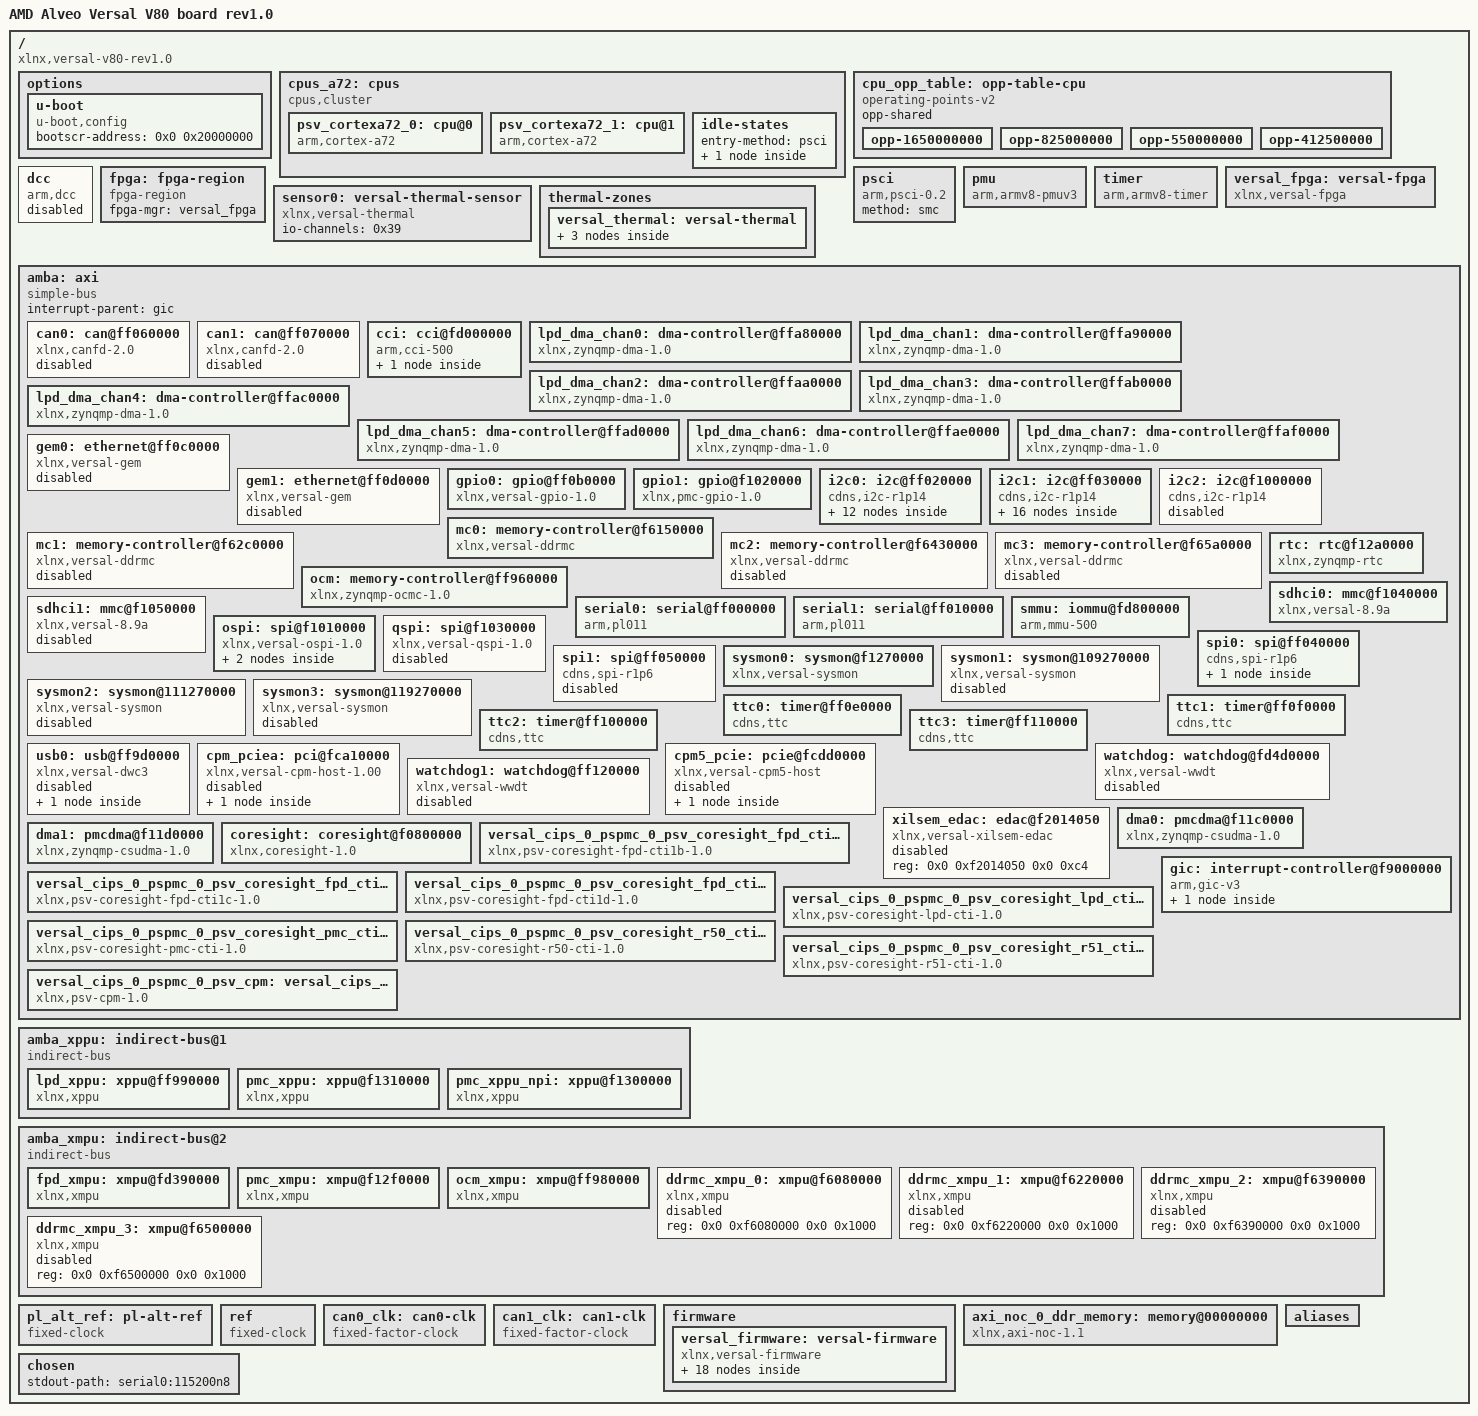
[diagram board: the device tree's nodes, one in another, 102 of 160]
/dts-v1/;
/ {
        compatible = "xlnx,versal-v80-rev1.0", "xlnx,versal";
        #address-cells = <0x2>;
        #size-cells = <0x2>;
        model = "AMD Alveo Versal V80 board rev1.0";
        board = "v80";
        device_id = "xcv80";
        slrcount = <0x3>;
        family = "Versal";
        speed_grade = "2MHP";

        options {

                u-boot {
                        compatible = "u-boot,config";
                        bootscr-address = <0x0 0x20000000>;
                };
        };

        cpus_a72: cpus {
                #address-cells = <0x1>;
                #size-cells = <0x0>;
                compatible = "cpus,cluster";
                #ranges-address-cells = <0x2>;
                #ranges-size-cells = <0x2>;
                phandle = <0x9e>;

                psv_cortexa72_0: cpu@0 {
                        compatible = "arm,cortex-a72", "arm,armv8";
                        device_type = "cpu";
                        enable-method = "psci";
                        operating-points-v2 = <&cpu_opp_table>;
                        reg = <0x0>;
                        cpu-idle-states = <&CPU_SLEEP_0>;
                        power-domains = <&versal_firmware 0x18110003>;
                        clocks = <&versal_clk 0x4d>;
                        xlnx,timestamp-clk-freq = <0x5f5e0a4>;
                        xlnx,pss-ref-clk-freq = <0x1fca034>;
                        stamp-frequency = <0x5f5e0a4>;
                        xlnx,ip-name = "psv_cortexa72";
                        xlnx,cpu-clk-freq-hz = <0x6258fa4d>;
                        cpu-frequency = <0x6258fa4d>;
                        bus-handle = <0x1>;
                        phandle = <0x9f>;
                };

                psv_cortexa72_1: cpu@1 {
                        compatible = "arm,cortex-a72", "arm,armv8";
                        device_type = "cpu";
                        enable-method = "psci";
                        operating-points-v2 = <&cpu_opp_table>;
                        reg = <0x1>;
                        cpu-idle-states = <&CPU_SLEEP_0>;
                        power-domains = <&versal_firmware 0x18110004>;
                        xlnx,timestamp-clk-freq = <0x5f5e0a4>;
                        xlnx,pss-ref-clk-freq = <0x1fca034>;
                        stamp-frequency = <0x5f5e0a4>;
                        xlnx,ip-name = "psv_cortexa72";
                        xlnx,cpu-clk-freq-hz = <0x6258fa4d>;
                        cpu-frequency = <0x6258fa4d>;
                        bus-handle = <0x1>;
                        phandle = <0xa0>;
                };

                idle-states {
                        entry-method = "psci";

                        CPU_SLEEP_0: cpu-sleep-0 {
                                compatible = "arm,idle-state";
                                arm,psci-suspend-param = <0x40000000>;
                                local-timer-stop;
                                entry-latency-us = <0x12c>;
                                exit-latency-us = <0x258>;
                                min-residency-us = <0x2710>;
                                phandle = <0x73>;
                        };
                };
        };

        cpu_opp_table: opp-table-cpu {
                compatible = "operating-points-v2";
                opp-shared;
                phandle = <0x72>;

                opp-1650000000 {
                        opp-hz = <0x0 0x62590080>;
                        clock-latency-ns = <0x7a120>;
                        opp-microvolt = <0xf4240>;
                };

                opp-825000000 {
                        opp-hz = <0x0 0x312c8040>;
                        clock-latency-ns = <0x7a120>;
                        opp-microvolt = <0xf4240>;
                };

                opp-550000000 {
                        opp-hz = <0x0 0x20c85580>;
                        clock-latency-ns = <0x7a120>;
                        opp-microvolt = <0xf4240>;
                };

                opp-412500000 {
                        opp-hz = <0x0 0x18964020>;
                        clock-latency-ns = <0x7a120>;
                        opp-microvolt = <0xf4240>;
                };
        };

        dcc: dcc {
                compatible = "arm,dcc";
                status = "disabled";
                bootph-all;
                phandle = <0xa9>;
        };

        fpga: fpga-region {
                compatible = "fpga-region";
                fpga-mgr = <&versal_fpga>;
                #address-cells = <0x2>;
                #size-cells = <0x2>;
                phandle = <0xaa>;
        };

        psci: psci {
                compatible = "arm,psci-0.2";
                method = "smc";
                phandle = <0xab>;
        };

        pmu {
                compatible = "arm,armv8-pmuv3";
                interrupt-parent = <&gic>;
                interrupts = <0x1 0x7 0x304>;
        };

        timer: timer {
                compatible = "arm,armv8-timer";
                interrupt-parent = <&gic>;
                interrupts = <0x1 0xd 0x4 0x1 0xe 0x4 0x1 0xb 0x4 0x1 0xa 0x4>;
                phandle = <0xac>;
        };

        versal_fpga: versal-fpga {
                compatible = "xlnx,versal-fpga";
                phandle = <0x92>;
        };

        sensor0: versal-thermal-sensor {
                compatible = "xlnx,versal-thermal";
                #thermal-sensor-cells = <0x0>;
                io-channels = <0x39>;
                io-channel-names = "sysmon-temp-channel";
                phandle = <0x94>;
        };

        thermal-zones {

                versal_thermal: versal-thermal {
                        polling-delay-passive = <0xfa>;
                        polling-delay = <0x3e8>;
                        thermal-sensors = <0x94>;
                        phandle = <0xad>;

                        trips {

                                temp_alert: temp-alert {
                                        temperature = <0x11170>;
                                        hysteresis = <0x0>;
                                        type = "passive";
                                        phandle = <0xae>;
                                };

                                ot_crit: ot-crit {
                                        temperature = <0x1e848>;
                                        hysteresis = <0x0>;
                                        type = "critical";
                                        phandle = <0xaf>;
                                };
                        };
                };
        };

        amba: axi {
                compatible = "simple-bus";
                #address-cells = <0x2>;
                #size-cells = <0x2>;
                ranges;
                interrupt-parent = <&gic>;
                bootph-all;
                phandle = <0x1>;

                can0: can@ff060000 {
                        compatible = "xlnx,canfd-2.0";
                        status = "disabled";
                        reg = <0x0 0xff060000 0x0 0x6000>;
                        interrupts = <0x0 0x14 0x4>;
                        interrupt-parent = <&gic>;
                        clock-names = "can_clk", "s_axi_aclk";
                        rx-fifo-depth = <0x40>;
                        tx-mailbox-count = <0x20>;
                        clocks = <&can0_clk>,
                         <&versal_clk 0x52>;
                        power-domains = <&versal_firmware 0x1822401f>;
                        phandle = <0xb0>;
                };

                can1: can@ff070000 {
                        compatible = "xlnx,canfd-2.0";
                        status = "disabled";
                        reg = <0x0 0xff070000 0x0 0x6000>;
                        interrupts = <0x0 0x15 0x4>;
                        interrupt-parent = <&gic>;
                        clock-names = "can_clk", "s_axi_aclk";
                        rx-fifo-depth = <0x40>;
                        tx-mailbox-count = <0x20>;
                        clocks = <&can1_clk>,
                         <&versal_clk 0x52>;
                        power-domains = <&versal_firmware 0x18224020>;
                        phandle = <0xb1>;
                };

                cci: cci@fd000000 {
                        compatible = "arm,cci-500";
                        status = "okay";
                        reg = <0x0 0xfd000000 0x0 0x10000>;
                        ranges = <0x0 0x0 0xfd000000 0xa0000>;
                        #address-cells = <0x1>;
                        #size-cells = <0x1>;
                        xlnx,ip-name = "psv_fpd_maincci";
                        phandle = <0x44>;

                        cci_pmu: pmu@10000 {
                                compatible = "arm,cci-500-pmu,r0";
                                reg = <0x10000 0x90000>;
                                interrupt-parent = <&gic>;
                                interrupts = <0x0 0x6a 0x4 0x0 0x6a 0x4 0x0 0x6a 0x4 0x0 0x6a 0x4 0x0 0x6a 0x4 0x0 0x6a 0x4 0x0 0x6a 0x4 0x0 0x6a 0x4>;
                                phandle = <0xb2>;
                        };
                };

                lpd_dma_chan0: dma-controller@ffa80000 {
                        compatible = "xlnx,zynqmp-dma-1.0";
                        status = "okay";
                        reg = <0x0 0xffa80000 0x0 0x1000>;
                        interrupts = <0x0 0x3c 0x4>;
                        interrupt-parent = <&gic>;
                        clock-names = "clk_main", "clk_apb";
                        xlnx,dma-type = <0x1>;
                        #dma-cells = <0x1>;
                        xlnx,bus-width = <0x40>;
                        clocks = <&versal_clk 0x51>,
                         <&versal_clk 0x52>;
                        power-domains = <&versal_firmware 0x18224035>;
                        xlnx,is-cache-coherent = <0x0>;
                        xlnx,ip-name = "psv_adma";
                        xlnx,dma-mode = <0x1>;
                        phandle = <0x66>;
                };

                lpd_dma_chan1: dma-controller@ffa90000 {
                        compatible = "xlnx,zynqmp-dma-1.0";
                        status = "okay";
                        reg = <0x0 0xffa90000 0x0 0x1000>;
                        interrupts = <0x0 0x3d 0x4>;
                        interrupt-parent = <&gic>;
                        clock-names = "clk_main", "clk_apb";
                        xlnx,dma-type = <0x1>;
                        #dma-cells = <0x1>;
                        xlnx,bus-width = <0x40>;
                        clocks = <&versal_clk 0x51>,
                         <&versal_clk 0x52>;
                        power-domains = <&versal_firmware 0x18224036>;
                        xlnx,is-cache-coherent = <0x0>;
                        xlnx,ip-name = "psv_adma";
                        xlnx,dma-mode = <0x1>;
                        phandle = <0x67>;
                };

                lpd_dma_chan2: dma-controller@ffaa0000 {
                        compatible = "xlnx,zynqmp-dma-1.0";
                        status = "okay";
                        reg = <0x0 0xffaa0000 0x0 0x1000>;
                        interrupts = <0x0 0x3e 0x4>;
                        interrupt-parent = <&gic>;
                        clock-names = "clk_main", "clk_apb";
                        xlnx,dma-type = <0x1>;
                        #dma-cells = <0x1>;
                        xlnx,bus-width = <0x40>;
                        clocks = <&versal_clk 0x51>,
                         <&versal_clk 0x52>;
                        power-domains = <&versal_firmware 0x18224037>;
                        xlnx,is-cache-coherent = <0x0>;
                        xlnx,ip-name = "psv_adma";
                        xlnx,dma-mode = <0x1>;
                        phandle = <0x68>;
                };

                lpd_dma_chan3: dma-controller@ffab0000 {
                        compatible = "xlnx,zynqmp-dma-1.0";
                        status = "okay";
                        reg = <0x0 0xffab0000 0x0 0x1000>;
                        interrupts = <0x0 0x3f 0x4>;
                        interrupt-parent = <&gic>;
                        clock-names = "clk_main", "clk_apb";
                        xlnx,dma-type = <0x1>;
                        #dma-cells = <0x1>;
                        xlnx,bus-width = <0x40>;
                        clocks = <&versal_clk 0x51>,
                         <&versal_clk 0x52>;
                        power-domains = <&versal_firmware 0x18224038>;
                        xlnx,is-cache-coherent = <0x0>;
                        xlnx,ip-name = "psv_adma";
                        xlnx,dma-mode = <0x1>;
                        phandle = <0x69>;
                };

                lpd_dma_chan4: dma-controller@ffac0000 {
                        compatible = "xlnx,zynqmp-dma-1.0";
                        status = "okay";
                        reg = <0x0 0xffac0000 0x0 0x1000>;
                        interrupts = <0x0 0x40 0x4>;
                        interrupt-parent = <&gic>;
                        clock-names = "clk_main", "clk_apb";
                        xlnx,dma-type = <0x1>;
                        #dma-cells = <0x1>;
                        xlnx,bus-width = <0x40>;
                        clocks = <&versal_clk 0x51>,
                         <&versal_clk 0x52>;
                        power-domains = <&versal_firmware 0x18224039>;
                        xlnx,is-cache-coherent = <0x0>;
                        xlnx,ip-name = "psv_adma";
                        xlnx,dma-mode = <0x1>;
                        phandle = <0x6a>;
                };

                lpd_dma_chan5: dma-controller@ffad0000 {
                        compatible = "xlnx,zynqmp-dma-1.0";
                        status = "okay";
                        reg = <0x0 0xffad0000 0x0 0x1000>;
                        interrupts = <0x0 0x41 0x4>;
                        interrupt-parent = <&gic>;
                        clock-names = "clk_main", "clk_apb";
                        xlnx,dma-type = <0x1>;
                        #dma-cells = <0x1>;
                        xlnx,bus-width = <0x40>;
                        clocks = <&versal_clk 0x51>,
                         <&versal_clk 0x52>;
                        power-domains = <&versal_firmware 0x1822403a>;
                        xlnx,is-cache-coherent = <0x0>;
                        xlnx,ip-name = "psv_adma";
                        xlnx,dma-mode = <0x1>;
                        phandle = <0x6b>;
                };

                lpd_dma_chan6: dma-controller@ffae0000 {
                        compatible = "xlnx,zynqmp-dma-1.0";
                        status = "okay";
                        reg = <0x0 0xffae0000 0x0 0x1000>;
                        interrupts = <0x0 0x42 0x4>;
                        interrupt-parent = <&gic>;
                        clock-names = "clk_main", "clk_apb";
                        xlnx,dma-type = <0x1>;
                        #dma-cells = <0x1>;
                        xlnx,bus-width = <0x40>;
                        clocks = <&versal_clk 0x51>,
                         <&versal_clk 0x52>;
                        power-domains = <&versal_firmware 0x1822403b>;
                        xlnx,is-cache-coherent = <0x0>;
                        xlnx,ip-name = "psv_adma";
                        xlnx,dma-mode = <0x1>;
                        phandle = <0x6c>;
                };

                lpd_dma_chan7: dma-controller@ffaf0000 {
                        compatible = "xlnx,zynqmp-dma-1.0";
                        status = "okay";
                        reg = <0x0 0xffaf0000 0x0 0x1000>;
                        interrupts = <0x0 0x43 0x4>;
                        interrupt-parent = <&gic>;
                        clock-names = "clk_main", "clk_apb";
                        xlnx,dma-type = <0x1>;
                        #dma-cells = <0x1>;
                        xlnx,bus-width = <0x40>;
                        clocks = <&versal_clk 0x51>,
                         <&versal_clk 0x52>;
                        power-domains = <&versal_firmware 0x1822403c>;
                        xlnx,is-cache-coherent = <0x0>;
                        xlnx,ip-name = "psv_adma";
                        xlnx,dma-mode = <0x1>;
                        phandle = <0x6d>;
                };

                gem0: ethernet@ff0c0000 {
                        compatible = "xlnx,versal-gem", "cdns,gem";
                        status = "disabled";
                        reg = <0x0 0xff0c0000 0x0 0x1000>;
                        interrupts = <0x0 0x38 0x4 0x0 0x38 0x4>;
                        interrupt-parent = <&gic>;
                        clock-names = "pclk", "hclk", "tx_clk", "rx_clk", "tsu_clk";
                        #address-cells = <0x1>;
                        #size-cells = <0x0>;
                        clocks = <&versal_clk 0x52>,
                         <&versal_clk 0x58>,
                         <&versal_clk 0x31>,
                         <&versal_clk 0x30>,
                         <&versal_clk 0x2b>;
                        power-domains = <&versal_firmware 0x18224019>;
                        phandle = <0xb3>;
                };

                gem1: ethernet@ff0d0000 {
                        compatible = "xlnx,versal-gem", "cdns,gem";
                        status = "disabled";
                        reg = <0x0 0xff0d0000 0x0 0x1000>;
                        interrupts = <0x0 0x3a 0x4 0x0 0x3a 0x4>;
                        interrupt-parent = <&gic>;
                        clock-names = "pclk", "hclk", "tx_clk", "rx_clk", "tsu_clk";
                        #address-cells = <0x1>;
                        #size-cells = <0x0>;
                        clocks = <&versal_clk 0x52>,
                         <&versal_clk 0x59>,
                         <&versal_clk 0x33>,
                         <&versal_clk 0x32>,
                         <&versal_clk 0x2b>;
                        power-domains = <&versal_firmware 0x1822401a>;
                        phandle = <0xb4>;
                };

                gpio0: gpio@ff0b0000 {
                        compatible = "xlnx,versal-gpio-1.0";
                        status = "okay";
                        reg = <0x0 0xff0b0000 0x0 0x1000>;
                        interrupts = <0x0 0xd 0x4>;
                        interrupt-parent = <&gic>;
                        #gpio-cells = <0x2>;
                        gpio-controller;
                        #interrupt-cells = <0x2>;
                        interrupt-controller;
                        clocks = <&versal_clk 0x52>;
                        power-domains = <&versal_firmware 0x18224023>;
                        xlnx,ip-name = "psv_gpio";
                        emio-gpio-width = "";
                        gpio-line-names = [49 32 43 5F 51 53 46 50 5F 53 43 4C 00 49 32 43 5F 51 53 46 50 5F 53 44 41 00 49 32 43 5F 4D 41 49 4E 5F 53 43 4C 00 49 32 43 5F 4D 41 49 4E 5F 53 44 41 00 49 32 43 5F 4D 41 49 4E 5F 52 53 54 5F 42 00 49 32 43 5F 4D 41 49 4E 5F 49 4E 54 52 5F 42 00 51 53 46 50 34 5F 49 4F 45 58 50 5F 52 53 54 00 51 53 46 50 33 5F 49 4F 45 58 50 5F 52 53 54 00 4C 50 44 5F 55 41 52 54 30 5F 52 58 44 00 4C 50 44 5F 55 41 52 54 30 5F 54 58 44 00 00 00 53 50 49 30 5F 53 43 4C 4B 00 49 32 43 5F 51 53 46 50 5F 52 53 54 5F 42 00 49 32 43 5F 51 53 46 50 5F 49 4E 54 52 5F 42 00 53 50 49 30 5F 43 53 5F 42 00 53 50 49 30 5F 4D 49 53 4F 00 53 50 49 30 5F 4D 4F 53 49 00 51 53 46 50 31 5F 49 4F 45 58 50 5F 52 53 54 00 51 53 46 50 32 5F 49 4F 45 58 50 5F 52 53 54 00 4C 50 44 5F 55 41 52 54 31 5F 54 58 44 00 4C 50 44 5F 55 41 52 54 31 5F 52 58 44 00 42 4F 41 52 44 5F 53 54 41 54 55 53 5F 4C 45 44 5F 52 00 42 4F 41 52 44 5F 53 54 41 54 55 53 5F 4C 45 44 5F 47 00 42 4F 41 52 44 5F 53 54 41 54 55 53 5F 4C 45 44 5F 42 00 00 00 00 00 00 00 00 00 00 00 00 00 00 00 00 00 00 00 00 00 00 00 00 00 00 00 00 00 00 00 00 00 00];
                        phandle = <0x57>;
                };

                gpio1: gpio@f1020000 {
                        compatible = "xlnx,pmc-gpio-1.0";
                        status = "okay";
                        reg = <0x0 0xf1020000 0x0 0x1000>;
                        interrupts = <0x0 0x7a 0x4>;
                        interrupt-parent = <&gic>;
                        #gpio-cells = <0x2>;
                        gpio-controller;
                        #interrupt-cells = <0x2>;
                        interrupt-controller;
                        clocks = <&versal_clk 0x3d>;
                        power-domains = <&versal_firmware 0x1822402c>;
                        xlnx,ip-name = "psv_pmc_gpio";
                        gpio-line-names = [00 00 00 00 00 00 00 00 00 00 00 42 4F 41 52 44 5F 49 44 00 4F 53 50 49 5F 52 45 53 45 54 5F 42 00 00 00 00 00 00 00 00 00 00 00 00 50 43 49 45 5F 52 53 54 31 5F 42 00 50 43 49 45 5F 52 53 54 32 5F 42 00 51 53 46 50 34 5F 41 43 54 5F 4C 45 44 00 51 53 46 50 34 5F 4C 4E 4B 5F 47 52 5F 4C 45 44 00 51 53 46 50 34 5F 4C 4E 4B 5F 59 4C 5F 4C 45 44 00 45 4E 5F 33 56 33 5F 4D 43 49 4F 00 51 53 46 50 33 5F 41 43 54 5F 4C 45 44 00 51 53 46 50 33 5F 4C 4E 4B 5F 47 52 5F 4C 45 44 00 51 53 46 50 33 5F 4C 4E 4B 5F 59 4C 5F 4C 45 44 00 50 47 5F 33 56 33 5F 4D 43 49 4F 00 51 53 46 50 31 5F 41 43 54 5F 4C 45 44 00 51 53 46 50 31 5F 4C 4E 4B 5F 47 52 5F 4C 45 44 00 51 53 46 50 31 5F 4C 4E 4B 5F 59 4C 5F 4C 45 44 00 00 51 53 46 50 32 5F 41 43 54 5F 4C 45 44 00 51 53 46 50 32 5F 4C 4E 4B 5F 47 52 5F 4C 45 44 00 51 53 46 50 32 5F 4C 4E 4B 5F 59 4C 5F 4C 45 44 00 50 47 5F 31 32 56 5F 41 55 58 32 00 50 43 49 45 5F 45 58 50 31 5F 50 45 52 53 54 42 00 50 43 49 45 5F 45 58 50 32 5F 50 45 52 53 54 42 00 50 43 49 45 5F 45 58 50 33 5F 50 45 52 53 54 42 00 4D 43 49 4F 5F 50 32 5F 46 4C 45 58 49 4F 30 5F 42 55 46 00 50 4D 43 5F 55 41 52 54 31 5F 54 58 44 00 50 4D 43 5F 55 41 52 54 31 5F 52 58 44 00 50 43 49 45 5F 45 58 50 31 5F 43 50 52 53 4E 54 42 00 50 43 49 45 5F 45 58 50 32 5F 43 50 52 53 4E 54 42 00 50 43 49 45 5F 45 58 50 33 5F 43 50 52 53 4E 54 42 00 55 53 42 5F 50 52 45 53 00 00 00 00 00 00 00 00 00 00 00 00 00 00 00 00 00 00 00 00 00 00 00 00 00 00 00 00 00 00 00 00 00 00 00 00 00 00 00 00 00 00 00 00 00 00 00 00 00 00 00 00 00 00 00 00 00 00 00 00 00 00 00 00 00];
                        phandle = <0x2b>;
                };

                i2c0: i2c@ff020000 {
                        compatible = "cdns,i2c-r1p14";
                        status = "okay";
                        reg = <0x0 0xff020000 0x0 0x1000>;
                        interrupts = <0x0 0xe 0x4>;
                        interrupt-parent = <&gic>;
                        clock-frequency = <0x186a0>;
                        #address-cells = <0x1>;
                        #size-cells = <0x0>;
                        clocks = <&versal_clk 0x62>;
                        power-domains = <&versal_firmware 0x1822401d>;
                        xlnx,clock-freq = <0x5f5e0a4>;
                        xlnx,i2c-clk-freq-hz = <0x5f5e0a4>;
                        xlnx,ip-name = "psv_i2c";
                        xlnx,iic-board-interface = "custom";
                        phandle = <0x52>;

                        regulator_u50: regulator@60 {
                                compatible = "isil,isl68224";
                                reg = <0x60>;
                                phandle = <0xb5>;
                        };

                        regulator_uXX: regulator@61 {
                                compatible = "isil,isl68224";
                                reg = <0x61>;
                                phandle = <0xb6>;
                        };

                        sensor_u30: temp-sensor@1a {
                                compatible = "onnn,cat34ts02", "jedec,jc-42.4-temp";
                                reg = <0x1a>;
                                phandle = <0xb7>;
                        };

                        gpio_u43: gpio@20 {
                                compatible = "ti,tca6416";
                                reg = <0x20>;
                                gpio-controller;
                                #gpio-cells = <0x2>;
                                interrupt-parent = <&gpio0>;
                                interrupts = <0x5 0x1>;
                                gpio-line-names = "TCRITn", "EN_VCC_FUSE", "FRU_EEPRM_WP", "PCIE_SMB_LT_EN", "IOEXP_POR_B", "CG_CONFI_GPIO0", "EN_DIMM", "DMB_PRSNT_B", "12V_AUX1_SENSE0_N", "12V_AUX1_SENSE1_N", "12V_AUX2_SENSE0_N", "12V_AUX2_SENSE1_N", "PG_3V3_QSFP", "DIMM_PWRGD", "BRD_PWRGD", "HBM_PWRGD";
                                phandle = <0xb8>;
                        };

                        ina_u48: power-sensor@40 {
                                compatible = "ti,ina3221";
                                reg = <0x40>;
                                #address-cells = <0x1>;
                                #size-cells = <0x0>;
                                phandle = <0xb9>;

                                input@0 {
                                        reg = <0x0>;
                                        label = "VR_12V";
                                        shunt-resistor-micro-ohms = <0x7d0>;
                                };

                                input@1 {
                                        reg = <0x1>;
                                        label = "VR_3V3";
                                        shunt-resistor-micro-ohms = <0x7d0>;
                                };

                                input@2 {
                                        reg = <0x2>;
                                        label = "VR_3V3_QSFP";
                                        shunt-resistor-micro-ohms = <0x7d0>;
                                };
                        };

                        ina_u49: power-sensor@41 {
                                compatible = "ti,ina3221";
                                reg = <0x41>;
                                #address-cells = <0x1>;
                                #size-cells = <0x0>;
                                phandle = <0xba>;

                                input@0 {
                                        reg = <0x0>;
                                        label = "VR_1V2_VCCO_DIMM";
                                        shunt-resistor-micro-ohms = <0x7d0>;
                                };

                                input@1 {
                                        reg = <0x1>;
                                        label = "VR_12V_AUX1";
                                        shunt-resistor-micro-ohms = <0x7d0>;
                                };

                                input@2 {
                                        reg = <0x2>;
                                        label = "VR_12V_AUX2";
                                        shunt-resistor-micro-ohms = <0x7d0>;
                                };
                        };
                };

                i2c1: i2c@ff030000 {
                        compatible = "cdns,i2c-r1p14";
                        status = "okay";
                        reg = <0x0 0xff030000 0x0 0x1000>;
                        interrupts = <0x0 0xf 0x4>;
                        interrupt-parent = <&gic>;
                        clock-frequency = <0x186a0>;
                        #address-cells = <0x1>;
                        #size-cells = <0x0>;
                        clocks = <&versal_clk 0x63>;
                        power-domains = <&versal_firmware 0x1822401e>;
                        xlnx,clock-freq = <0x5f5e0a4>;
                        xlnx,i2c-clk-freq-hz = <0x5f5e0a4>;
                        xlnx,ip-name = "psv_i2c";
                        xlnx,iic-board-interface = "custom";
                        phandle = <0x53>;

                        qsfp_power: gpio@21 {
                                compatible = "ti,tca6408";
                                reg = <0x21>;
                                gpio-controller;
                                #gpio-cells = <0x2>;
                                interrupt-parent = <&gpio0>;
                                interrupts = <0xe 0x1>;
                                gpio-line-names = "EN_3V3_QSFP1", "EN_3V3_QSFP2", "EN_3V3_QSFP3", "EN_3V3_QSFP4", "PG_3V3_QSFP1", "PG_3V3_QSFP2", "PG_3V3_QSFP3", "PG_3V3_QSFP4";
                                phandle = <0xbb>;
                        };

                        i2c_qsfp1: i2c-mux@70 {
                                compatible = "nxp,pca9545";
                                #address-cells = <0x1>;
                                #size-cells = <0x0>;
                                #interrupt-cells = <0x2>;
                                reg = <0x70>;
                                interrupt-parent = <&gpio0>;
                                interrupts = <0xe 0x1>;
                                interrupt-controller;
                                phandle = <0x97>;

                                i2c@0 {
                                        #address-cells = <0x1>;
                                        #size-cells = <0x0>;
                                        reg = <0x0>;

                                        qsfp1: gpio@20 {
                                                compatible = "ti,tca6408";
                                                reg = <0x20>;
                                                gpio-controller;
                                                #gpio-cells = <0x2>;
                                                interrupt-parent = <&i2c_qsfp1>;
                                                interrupts = <0x2 0x1>;
                                                gpio-line-names = "QSFP1_MODSELL", "QSFP1_RESETL", "QSFP1_LPMODE", "QSFP1_MODPRSL", "QSFP1_INTR_B", "", "", "";
                                                phandle = <0xbc>;
                                        };
                                };

                                i2c@1 {
                                        #address-cells = <0x1>;
                                        #size-cells = <0x0>;
                                        reg = <0x1>;
                                };

                                i2c@2 {
                                        #address-cells = <0x1>;
                                        #size-cells = <0x0>;
                                        reg = <0x2>;

                                        qsfp2: gpio@20 {
                                                compatible = "ti,tca6408";
                                                reg = <0x20>;
                                                gpio-controller;
                                                #gpio-cells = <0x2>;
                                                interrupt-parent = <&i2c_qsfp1>;
                                                interrupts = <0x2 0x1>;
                                                gpio-line-names = "QSFP2_MODSELL", "QSFP2_RESETL", "QSFP2_LPMODE", "QSFP2_MODPRSL", "QSFP2_INTR_B", "", "", "";
                                                phandle = <0xbd>;
                                        };
                                };

                                i2c@3 {
                                        #address-cells = <0x1>;
                                        #size-cells = <0x0>;
                                        reg = <0x3>;
                                };
                        };

                        i2c_qsfp3: i2c-mux@71 {
                                compatible = "nxp,pca9545";
                                #address-cells = <0x1>;
                                #size-cells = <0x0>;
                                #interrupt-cells = <0x2>;
                                reg = <0x70>;
                                interrupt-parent = <&gpio0>;
                                interrupts = <0xe 0x1>;
                                interrupt-controller;
                                phandle = <0x98>;

                                i2c@0 {
                                        #address-cells = <0x1>;
                                        #size-cells = <0x0>;
                                        reg = <0x0>;

                                        qsfp3: gpio@20 {
                                                compatible = "ti,tca6408";
                                                reg = <0x20>;
                                                gpio-controller;
                                                #gpio-cells = <0x2>;
                                                interrupt-parent = <&i2c_qsfp3>;
                                                interrupts = <0x2 0x1>;
                                                gpio-line-names = "QSFP3_MODSELL", "QSFP3_RESETL", "QSFP3_LPMODE", "QSFP3_MODPRSL", "QSFP3_INTR_B", "", "", "";
                                                phandle = <0xbe>;
                                        };
                                };

                                i2c@1 {
                                        #address-cells = <0x1>;
                                        #size-cells = <0x0>;
                                        reg = <0x1>;
                                };

                                i2c@2 {
                                        #address-cells = <0x1>;
                                        #size-cells = <0x0>;
                                        reg = <0x2>;

                                        qsfp4: gpio@20 {
                                                compatible = "ti,tca6408";
                                                reg = <0x20>;
                                                gpio-controller;
                                                #gpio-cells = <0x2>;
                                                interrupt-parent = <&i2c_qsfp3>;
                                                interrupts = <0x2 0x1>;
                                                gpio-line-names = "QSFP4_MODSELL", "QSFP4_RESETL", "QSFP4_LPMODE", "QSFP4_MODPRSL", "QSFP4_INTR_B", "", "", "";
                                                phandle = <0xbf>;
                                        };
                                };

                                i2c@3 {
                                        #address-cells = <0x1>;
                                        #size-cells = <0x0>;
                                        reg = <0x3>;
                                };
                        };

                        pcie: i2c-mux@72 {
                                compatible = "nxp,pca9545";
                                #address-cells = <0x1>;
                                #size-cells = <0x0>;
                                #interrupt-cells = <0x2>;
                                reg = <0x72>;
                                interrupt-parent = <&gpio0>;
                                interrupts = <0xe 0x1>;
                                interrupt-controller;
                                phandle = <0xc0>;
                        };
                };

                i2c2: i2c@f1000000 {
                        compatible = "cdns,i2c-r1p14";
                        status = "disabled";
                        reg = <0x0 0xf1000000 0x0 0x1000>;
                        interrupts = <0x0 0x7b 0x4>;
                        interrupt-parent = <&gic>;
                        clock-frequency = <0x186a0>;
                        #address-cells = <0x1>;
                        #size-cells = <0x0>;
                        clocks = <&versal_clk 0x3e>;
                        power-domains = <&versal_firmware 0x1822402d>;
                        phandle = <0xc1>;
                };

                mc0: memory-controller@f6150000 {
                        compatible = "xlnx,versal-ddrmc";
                        status = "okay";
                        reg = <0x0 0xf6150000 0x0 0x2000 0x0 0xf6070000 0x0 0x20000>;
                        reg-names = "base", "noc";
                        interrupts = <0x0 0x93 0x4>;
                        interrupt-parent = <&gic>;
                        phandle = <0xc2>;
                };

                mc1: memory-controller@f62c0000 {
                        compatible = "xlnx,versal-ddrmc";
                        status = "disabled";
                        reg = <0x0 0xf62c0000 0x0 0x2000 0x0 0xf6210000 0x0 0x20000>;
                        reg-names = "base", "noc";
                        interrupts = <0x0 0x93 0x4>;
                        interrupt-parent = <&gic>;
                        phandle = <0xc3>;
                };

                mc2: memory-controller@f6430000 {
                        compatible = "xlnx,versal-ddrmc";
                        status = "disabled";
                        reg = <0x0 0xf6430000 0x0 0x2000 0x0 0xf6380000 0x0 0x20000>;
                        reg-names = "base", "noc";
                        interrupts = <0x0 0x93 0x4>;
                        interrupt-parent = <&gic>;
                        phandle = <0xc4>;
                };

                mc3: memory-controller@f65a0000 {
                        compatible = "xlnx,versal-ddrmc";
                        status = "disabled";
                        reg = <0x0 0xf65a0000 0x0 0x2000 0x0 0xf64f0000 0x0 0x20000>;
                        reg-names = "base", "noc";
                        interrupts = <0x0 0x93 0x4>;
                        interrupt-parent = <&gic>;
                        phandle = <0xc5>;
                };

                ocm: memory-controller@ff960000 {
                        compatible = "xlnx,zynqmp-ocmc-1.0";
                        reg = <0x0 0xff960000 0x0 0x1000>;
                        interrupts = <0x0 0xa 0x4>;
                        interrupt-parent = <&gic>;
                        phandle = <0xc6>;
                };

                rtc: rtc@f12a0000 {
                        compatible = "xlnx,zynqmp-rtc";
                        status = "okay";
                        reg = <0x0 0xf12a0000 0x0 0x100>;
                        interrupt-names = "alarm", "sec";
                        interrupts = <0x0 0x8e 0x4 0x0 0x8f 0x4>;
                        interrupt-parent = <&gic>;
                        calibration = <0x7fff>;
                        power-domains = <&versal_firmware 0x18224034>;
                        xlnx,ip-name = "psv_pmc_rtc";
                        phandle = <0x3a>;
                };

                sdhci0: mmc@f1040000 {
                        compatible = "xlnx,versal-8.9a", "arasan,sdhci-8.9a";
                        status = "okay";
                        reg = <0x0 0xf1040000 0x0 0x10000>;
                        interrupts = <0x0 0x7e 0x4>;
                        interrupt-parent = <&gic>;
                        clock-names = "clk_xin", "clk_ahb", "gate";
                        #clock-cells = <0x1>;
                        clock-output-names = "clk_out_sd0", "clk_in_sd0";
                        clocks = <&versal_clk 0x3b>,
                         <&versal_clk 0x52>,
                         <&versal_clk 0x4a>;
                        power-domains = <&versal_firmware 0x1822402e>;
                        xlnx,sd-board-interface = "custom";
                        xlnx,is-cache-coherent = <0x0>;
                        xlnx,clk-50-ddr-otap-dly = <0x5>;
                        xlnx,clk-50-sdr-itap-dly = <0x2c>;
                        xlnx,has-emio = <0x0>;
                        clock-frequency = <0xbebc149>;
                        xlnx,clk-100-sdr-otap-dly = <0x0>;
                        xlnx,mio-bank = <0x0>;
                        xlnx,ip-name = "psv_pmc_sd";
                        xlnx,bus-width = <0x8>;
                        xlnx,card-detect = <0x0>;
                        xlnx,has-wp = <0x0>;
                        xlnx,has-cd = <0x0>;
                        xlnx,slot-type = <0x1>;
                        xlnx,clk-50-sdr-otap-dly = <0x5>;
                        xlnx,clk-50-ddr-itap-dly = <0x1e>;
                        xlnx,has-power = <0x0>;
                        xlnx,clk-200-sdr-otap-dly = <0x2>;
                        xlnx,sdio-clk-freq-hz = <0xbebc149>;
                        xlnx,write-protect = <0x0>;
                        non-removable;
                        disable-wp;
                        no-sd;
                        no-sdio;
                        cap-mmc-hw-reset;
                        bus-width = <0x8>;
                        phandle = <0x2c>;
                };

                sdhci1: mmc@f1050000 {
                        compatible = "xlnx,versal-8.9a", "arasan,sdhci-8.9a";
                        status = "disabled";
                        reg = <0x0 0xf1050000 0x0 0x10000>;
                        interrupts = <0x0 0x80 0x4>;
                        interrupt-parent = <&gic>;
                        clock-names = "clk_xin", "clk_ahb", "gate";
                        #clock-cells = <0x1>;
                        clock-output-names = "clk_out_sd1", "clk_in_sd1";
                        clocks = <&versal_clk 0x3c>,
                         <&versal_clk 0x52>,
                         <&versal_clk 0x4a>;
                        power-domains = <&versal_firmware 0x1822402f>;
                        phandle = <0xc7>;
                };

                serial0: serial@ff000000 {
                        compatible = "arm,pl011", "arm,primecell";
                        status = "okay";
                        reg = <0x0 0xff000000 0x0 0x1000>;
                        interrupts = <0x0 0x12 0x4>;
                        interrupt-parent = <&gic>;
                        reg-io-width = <0x4>;
                        clock-names = "uartclk", "apb_pclk";
                        bootph-all;
                        clocks = <&versal_clk 0x5c>,
                         <&versal_clk 0x52>;
                        power-domains = <&versal_firmware 0x18224021>;
                        xlnx,clock-freq = <0x5f5e0a4>;
                        u-boot,dm-pre-reloc;
                        xlnx,uart-board-interface = "custom";
                        xlnx,has-modem = <0x0>;
                        xlnx,ip-name = "psv_sbsauart";
                        xlnx,baudrate = <0x1c200>;
                        cts-override;
                        port-number = <0x0>;
                        xlnx,uart-clk-freq-hz = <0x5f5e0a4>;
                        phandle = <0x50>;
                };

                serial1: serial@ff010000 {
                        compatible = "arm,pl011", "arm,primecell";
                        status = "okay";
                        reg = <0x0 0xff010000 0x0 0x1000>;
                        interrupts = <0x0 0x13 0x4>;
                        interrupt-parent = <&gic>;
                        reg-io-width = <0x4>;
                        clock-names = "uartclk", "apb_pclk";
                        bootph-all;
                        clocks = <&versal_clk 0x5d>,
                         <&versal_clk 0x52>;
                        power-domains = <&versal_firmware 0x18224022>;
                        xlnx,clock-freq = <0x5f5e0a4>;
                        u-boot,dm-pre-reloc;
                        xlnx,uart-board-interface = "custom";
                        xlnx,has-modem = <0x0>;
                        xlnx,ip-name = "psv_sbsauart";
                        xlnx,baudrate = <0x1c200>;
                        cts-override;
                        port-number = <0x0>;
                        xlnx,uart-clk-freq-hz = <0x5f5e0a4>;
                        phandle = <0x51>;
                };

                smmu: iommu@fd800000 {
                        compatible = "arm,mmu-500";
                        status = "okay";
                        reg = <0x0 0xfd800000 0x0 0x40000>;
                        stream-match-mask = <0x7c00>;
                        #iommu-cells = <0x1>;
                        #global-interrupts = <0x1>;
                        interrupts = <0x0 0x6b 0x4 0x0 0x6b 0x4 0x0 0x6b 0x4 0x0 0x6b 0x4 0x0 0x6b 0x4 0x0 0x6b 0x4 0x0 0x6b 0x4 0x0 0x6b 0x4 0x0 0x6b 0x4 0x0 0x6b 0x4 0x0 0x6b 0x4 0x0 0x6b 0x4 0x0 0x6b 0x4 0x0 0x6b 0x4 0x0 0x6b 0x4 0x0 0x6b 0x4 0x0 0x6b 0x4 0x0 0x6b 0x4 0x0 0x6b 0x4 0x0 0x6b 0x4 0x0 0x6b 0x4 0x0 0x6b 0x4 0x0 0x6b 0x4 0x0 0x6b 0x4 0x0 0x6b 0x4 0x0 0x6b 0x4 0x0 0x6b 0x4 0x0 0x6b 0x4 0x0 0x6b 0x4 0x0 0x6b 0x4 0x0 0x6b 0x4 0x0 0x6b 0x4 0x0 0x6b 0x4>;
                        interrupt-parent = <&gic>;
                        xlnx,ip-name = "psv_fpd_smmutcu";
                        phandle = <0x4f>;
                };

                ospi: spi@f1010000 {
                        compatible = "xlnx,versal-ospi-1.0", "cdns,qspi-nor";
                        status = "okay";
                        reg = <0x0 0xf1010000 0x0 0x10000 0x0 0xc0000000 0x0 0x20000000>;
                        interrupts = <0x0 0x7c 0x4>;
                        interrupt-parent = <&gic>;
                        cdns,fifo-depth = <0x100>;
                        cdns,fifo-width = <0x4>;
                        cdns,is-dma = <0x1>;
                        cdns,trigger-address = <0xc0000000>;
                        #address-cells = <0x1>;
                        #size-cells = <0x0>;
                        clocks = <&versal_clk 0x3a>;
                        power-domains = <&versal_firmware 0x1822402a>;
                        reset-names = "qspi";
                        resets = <&versal_reset 0xc10402e>;
                        is-stacked = <0x0>;
                        xlnx,is-cache-coherent = <0x0>;
                        xlnx,clock-freq = <0xbebc149>;
                        xlnx,ip-name = "psv_pmc_ospi";
                        xlnx,ospi-clk-freq-hz = <0xbebc149>;
                        is-dual = <0x0>;
                        xlnx,ospi-mode = <0x0>;
                        bus-num = <0x2>;
                        num-cs = <0x1>;
                        phandle = <0x2a>;

                        ospi_flash: flash@0 {
                                compatible = "mt35xu02g", "micron,m25p80", "jedec,spi-nor";
                                reg = <0x0>;
                                #address-cells = <0x1>;
                                #size-cells = <0x1>;
                                cdns,read-delay = <0x0>;
                                cdns,tshsl-ns = <0x0>;
                                cdns,tsd2d-ns = <0x0>;
                                cdns,tchsh-ns = <0x1>;
                                cdns,tslch-ns = <0x1>;
                                spi-tx-bus-width = <0x8>;
                                spi-rx-bus-width = <0x8>;
                                spi-max-frequency = <0x1312d00>;
                                no-wp;
                                reset-gpios = <&gpio1 0xc 0x1>;
                                phandle = <0xc8>;

                                partition@0 {
                                        label = "spi0-flash0";
                                        reg = <0x0 0x8000000>;
                                };
                        };
                };

                qspi: spi@f1030000 {
                        compatible = "xlnx,versal-qspi-1.0";
                        status = "disabled";
                        reg = <0x0 0xf1030000 0x0 0x1000>;
                        interrupts = <0x0 0x7d 0x4>;
                        interrupt-parent = <&gic>;
                        clock-names = "ref_clk", "pclk";
                        #address-cells = <0x1>;
                        #size-cells = <0x0>;
                        clocks = <&versal_clk 0x39>,
                         <&versal_clk 0x52>;
                        power-domains = <&versal_firmware 0x1822402b>;
                        phandle = <0xc9>;
                };

                spi0: spi@ff040000 {
                        compatible = "cdns,spi-r1p6";
                        status = "okay";
                        reg = <0x0 0xff040000 0x0 0x1000>;
                        interrupts = <0x0 0x10 0x4>;
                        interrupt-parent = <&gic>;
                        clock-names = "ref_clk", "pclk";
                        #address-cells = <0x1>;
                        #size-cells = <0x0>;
                        clocks = <&versal_clk 0x5e>,
                         <&versal_clk 0x52>;
                        power-domains = <&versal_firmware 0x1822401b>;
                        xlnx,spi-board-interface = "custom";
                        xlnx,has-ss0 = <0x1>;
                        xlnx,ip-name = "psv_spi";
                        xlnx,has-ss1 = <0x0>;
                        num-cs = <0x1>;
                        xlnx,spi-clk-freq-hz = <0xbebc149>;
                        xlnx,has-ss2 = <0x0>;
                        phandle = <0x54>;

                        flash@0 {
                                compatible = "jedec,spi-nor";
                                spi-max-frequency = <0x7ed6b40>;
                                reg = <0x0>;
                        };
                };

                spi1: spi@ff050000 {
                        compatible = "cdns,spi-r1p6";
                        status = "disabled";
                        reg = <0x0 0xff050000 0x0 0x1000>;
                        interrupts = <0x0 0x11 0x4>;
                        interrupt-parent = <&gic>;
                        clock-names = "ref_clk", "pclk";
                        #address-cells = <0x1>;
                        #size-cells = <0x0>;
                        clocks = <&versal_clk 0x5f>,
                         <&versal_clk 0x52>;
                        power-domains = <&versal_firmware 0x1822401c>;
                        phandle = <0xca>;
                };

                sysmon0: sysmon@f1270000 {
                        compatible = "xlnx,versal-sysmon";
                        #io-channel-cells = <0x0>;
                        reg = <0x0 0xf1270000 0x0 0x4000>;
                        interrupts = <0x0 0x90 0x4>;
                        xlnx,numchannels = "";
                        #address-cells = <0x2>;
                        #size-cells = <0x2>;
                        xlnx,nodeid = <0x18224055>;
                        xlnx,sat-63-desc = "PS , FPD , satellite";
                        xlnx,sat-17-x = <0x35e5>;
                        xlnx,sat-1-desc = "PMC , system , ADC";
                        xlnx,sat-9-x = <0x6ed4>;
                        xlnx,sat-17-y = <0x676f>;
                        xlnx,sat-19-desc = "VNOC , satellite";
                        xlnx,sat-20-desc = "HBM , Satellite , (right)";
                        xlnx,sat-9-y = <0x772d>;
                        xlnx,sat-22-x = <0x21a7>;
                        xlnx,ip-name = "psv_pmc_sysmon";
                        xlnx,sat-22-y = <0x7362>;
                        xlnx,sat-16-desc = "HBM , Satellite , (left)";
                        xlnx,sat-9-desc = "Clocking , column , satellite";
                        xlnx,sat-26-x = <0xf56>;
                        xlnx,sat-28-desc = "Clocking , column , satellite";
                        xlnx,sat-26-y = <0x7cf2>;
                        xlnx,sat-10-x = <0x6ed4>;
                        xlnx,sat-64-x = <0x56b>;
                        xlnx,sat-2-x = <0x56b>;
                        xlnx,sat-10-y = <0x70fe>;
                        xlnx,sat-64-y = <0xf11>;
                        xlnx,sat-2-y = <0x649d>;
                        xlnx,sat-13-desc = "VNOC , satellite";
                        xlnx,sat-6-desc = "HBM , Satellite , (right)";
                        xlnx,sat-14-x = <0x4a23>;
                        xlnx,sat-6-x = <0x5f7a>;
                        xlnx,sat-25-desc = "Clocking , column , satellite";
                        xlnx,sat-14-y = <0x7362>;
                        xlnx,sat-6-y = <0x9780>;
                        xlnx,sat-10-desc = "Clocking , column , satellite";
                        xlnx,sat-18-x = <0x35e5>;
                        xlnx,sat-3-desc = "VNOC , satellite";
                        xlnx,sat-18-y = <0x7362>;
                        xlnx,sat-22-desc = "VNOC , satellite";
                        xlnx,sat-23-x = <0x21a7>;
                        xlnx,sat-23-y = <0x7f56>;
                        xlnx,sat-18-desc = "VNOC , satellite";
                        xlnx,sat-27-x = <0xf56>;
                        xlnx,sat-27-y = <0x772d>;
                        xlnx,sat-11-x = <0x6ed4>;
                        xlnx,sat-3-x = <0x5e61>;
                        xlnx,sat-11-y = <0x6b39>;
                        xlnx,sat-3-y = <0x676f>;
                        status = "okay";
                        xlnx,sat-15-desc = "VNOC , satellite";
                        xlnx,sat-15-x = <0x4a23>;
                        xlnx,sat-8-desc = "Clocking , column , satellite";
                        xlnx,sat-7-x = <0x6ed4>;
                        xlnx,sat-15-y = <0x7f56>;
                        xlnx,sat-7-y = <0x8321>;
                        xlnx,sat-27-desc = "Clocking , column , satellite";
                        xlnx,sat-12-desc = "Clocking , column , satellite";
                        xlnx,sat-19-x = <0x35e5>;
                        xlnx,sat-20-x = <0x3441>;
                        xlnx,sat-19-y = <0x7f56>;
                        xlnx,sat-20-y = <0x9780>;
                        xlnx,sat-5-desc = "VNOC , satellite";
                        xlnx,sat-24-desc = "HBM , Satellite , (left)";
                        xlnx,sat-24-x = <0x1ea8>;
                        xlnx,sat-24-y = <0x9780>;
                        xlnx,sat-64-desc = "PS , LPD , satellite";
                        xlnx,sat-2-desc = "PMC , user , ADC";
                        xlnx,sat-28-x = <0xf56>;
                        xlnx,sat-21-desc = "VNOC , satellite";
                        xlnx,sat-28-y = <0x70fe>;
                        xlnx,sat-12-x = <0x6ed4>;
                        xlnx,sat-4-x = <0x5e61>;
                        xlnx,sat-12-y = <0x650b>;
                        xlnx,sat-4-y = <0x7362>;
                        xlnx,sat-16-x = <0x49e0>;
                        xlnx,sat-17-desc = "VNOC , satellite";
                        xlnx,sat-8-x = <0x6ed4>;
                        xlnx,sat-16-y = <0x9780>;
                        xlnx,sat-8-y = <0x7cf2>;
                        xlnx,sat-21-x = <0x21a7>;
                        xlnx,sat-14-desc = "VNOC , satellite";
                        xlnx,sat-21-y = <0x676f>;
                        xlnx,sat-7-desc = "Clocking , column , satellite";
                        xlnx,sat-26-desc = "Clocking , column , satellite";
                        xlnx,sat-25-x = <0xf56>;
                        xlnx,sat-25-y = <0x8321>;
                        xlnx,sat-63-x = <0x56b>;
                        xlnx,sat-11-desc = "Clocking , column , satellite";
                        xlnx,sat-1-x = <0x56b>;
                        xlnx,sat-63-y = <0xf11>;
                        xlnx,sat-1-y = <0x649d>;
                        xlnx,sat-4-desc = "VNOC , satellite";
                        xlnx,sat-13-x = <0x4a23>;
                        xlnx,sat-23-desc = "VNOC , satellite";
                        xlnx,sat-5-x = <0x5e61>;
                        xlnx,sat-13-y = <0x676f>;
                        xlnx,sat-5-y = <0x7f56>;
                        phandle = <0x39>;
                };

                sysmon1: sysmon@109270000 {
                        compatible = "xlnx,versal-sysmon";
                        status = "disabled";
                        reg = <0x1 0x9270000 0x0 0x4000>;
                        xlnx,numchannels = "";
                        #address-cells = <0x1>;
                        #size-cells = <0x0>;
                        xlnx,nodeid = <0x18225055>;
                        phandle = <0xcb>;
                };

                sysmon2: sysmon@111270000 {
                        compatible = "xlnx,versal-sysmon";
                        status = "disabled";
                        reg = <0x1 0x11270000 0x0 0x4000>;
                        xlnx,numchannels = "";
                        #address-cells = <0x1>;
                        #size-cells = <0x0>;
                        xlnx,nodeid = <0x18226055>;
                        phandle = <0xcc>;
                };

                sysmon3: sysmon@119270000 {
                        compatible = "xlnx,versal-sysmon";
                        status = "disabled";
                        reg = <0x1 0x19270000 0x0 0x4000>;
                        xlnx,numchannels = "";
                        #address-cells = <0x1>;
                        #size-cells = <0x0>;
                        xlnx,nodeid = <0x18227055>;
                        phandle = <0xcd>;
                };

                ttc0: timer@ff0e0000 {
                        compatible = "cdns,ttc";
                        status = "okay";
                        interrupts = <0x0 0x25 0x4 0x0 0x26 0x4 0x0 0x27 0x4>;
                        interrupt-parent = <&gic>;
                        reg = <0x0 0xff0e0000 0x0 0x1000>;
                        timer-width = <0x20>;
                        clocks = <&versal_clk 0x27>;
                        power-domains = <&versal_firmware 0x18224024>;
                        xlnx,ttc-board-interface = "custom";
                        xlnx,ttc-clk2-freq-hz = <0x8f0d0f7>;
                        xlnx,ttc-clk1-clksrc = <0x0>;
                        xlnx,clock-freq = <0x8f0d0f7>;
                        xlnx,ttc-clk2-clksrc = <0x0>;
                        xlnx,ip-name = "psv_ttc";
                        xlnx,ttc-clk0-freq-hz = <0x8f0d0f7>;
                        xlnx,ttc-clk1-freq-hz = <0x8f0d0f7>;
                        xlnx,ttc-clk0-clksrc = <0x0>;
                        phandle = <0x58>;
                };

                ttc1: timer@ff0f0000 {
                        compatible = "cdns,ttc";
                        status = "okay";
                        interrupts = <0x0 0x28 0x4 0x0 0x29 0x4 0x0 0x2a 0x4>;
                        interrupt-parent = <&gic>;
                        reg = <0x0 0xff0f0000 0x0 0x1000>;
                        timer-width = <0x20>;
                        clocks = <&versal_clk 0x28>;
                        power-domains = <&versal_firmware 0x18224025>;
                        xlnx,ttc-board-interface = "custom";
                        xlnx,ttc-clk2-freq-hz = <0x8f0d0f7>;
                        xlnx,ttc-clk1-clksrc = <0x0>;
                        xlnx,clock-freq = <0x8f0d0f7>;
                        xlnx,ttc-clk2-clksrc = <0x0>;
                        xlnx,ip-name = "psv_ttc";
                        xlnx,ttc-clk0-freq-hz = <0x8f0d0f7>;
                        xlnx,ttc-clk1-freq-hz = <0x8f0d0f7>;
                        xlnx,ttc-clk0-clksrc = <0x0>;
                        phandle = <0x59>;
                };

                ttc2: timer@ff100000 {
                        compatible = "cdns,ttc";
                        status = "okay";
                        interrupts = <0x0 0x2b 0x4 0x0 0x2c 0x4 0x0 0x2d 0x4>;
                        interrupt-parent = <&gic>;
                        reg = <0x0 0xff100000 0x0 0x1000>;
                        timer-width = <0x20>;
                        clocks = <&versal_clk 0x29>;
                        power-domains = <&versal_firmware 0x18224026>;
                        xlnx,ttc-board-interface = "custom";
                        xlnx,ttc-clk2-freq-hz = <0x8f0d0f7>;
                        xlnx,ttc-clk1-clksrc = <0x0>;
                        xlnx,clock-freq = <0x8f0d0f7>;
                        xlnx,ttc-clk2-clksrc = <0x0>;
                        xlnx,ip-name = "psv_ttc";
                        xlnx,ttc-clk0-freq-hz = <0x8f0d0f7>;
                        xlnx,ttc-clk1-freq-hz = <0x8f0d0f7>;
                        xlnx,ttc-clk0-clksrc = <0x0>;
                        phandle = <0x5a>;
                };

                ttc3: timer@ff110000 {
                        compatible = "cdns,ttc";
                        status = "okay";
                        interrupts = <0x0 0x2e 0x4 0x0 0x2f 0x4 0x0 0x30 0x4>;
                        interrupt-parent = <&gic>;
                        reg = <0x0 0xff110000 0x0 0x1000>;
                        timer-width = <0x20>;
                        clocks = <&versal_clk 0x2a>;
                        power-domains = <&versal_firmware 0x18224027>;
                        xlnx,ttc-board-interface = "custom";
                        xlnx,ttc-clk2-freq-hz = <0x8f0d0f7>;
                        xlnx,ttc-clk1-clksrc = <0x0>;
                        xlnx,clock-freq = <0x8f0d0f7>;
                        xlnx,ttc-clk2-clksrc = <0x0>;
                        xlnx,ip-name = "psv_ttc";
                        xlnx,ttc-clk0-freq-hz = <0x8f0d0f7>;
                        xlnx,ttc-clk1-freq-hz = <0x8f0d0f7>;
                        xlnx,ttc-clk0-clksrc = <0x0>;
                        phandle = <0x5b>;
                };

                usb0: usb@ff9d0000 {
                        compatible = "xlnx,versal-dwc3";
                        status = "disabled";
                        reg = <0x0 0xff9d0000 0x0 0x100>;
                        clock-names = "bus_clk", "ref_clk";
                        ranges;
                        #address-cells = <0x2>;
                        #size-cells = <0x2>;
                        clocks = <&versal_clk 0x5b>,
                         <&versal_clk 0x68>;
                        power-domains = <&versal_firmware 0x18224018>;
                        resets = <&versal_reset 0xc104036>;
                        phandle = <0xce>;

                        dwc3_0: usb@fe200000 {
                                compatible = "snps,dwc3";
                                status = "disabled";
                                reg = <0x0 0xfe200000 0x0 0x10000>;
                                interrupt-names = "host", "peripheral", "otg", "wakeup";
                                interrupts = <0x0 0x16 0x4 0x0 0x16 0x4 0x0 0x1a 0x4 0x0 0x4a 0x4>;
                                interrupt-parent = <&gic>;
                                snps,dis_u2_susphy_quirk;
                                snps,dis_u3_susphy_quirk;
                                snps,quirk-frame-length-adjustment = <0x20>;
                                clock-names = "ref";
                                clocks = <&versal_clk 0x5b>;
                                phandle = <0xcf>;
                        };
                };

                cpm_pciea: pci@fca10000 {
                        device_type = "pci";
                        #address-cells = <0x3>;
                        #interrupt-cells = <0x1>;
                        #size-cells = <0x2>;
                        compatible = "xlnx,versal-cpm-host-1.00";
                        status = "disabled";
                        interrupt-map = <0x0 0x0 0x0 0x1 &pcie_intc_0 0x0>,
                         <0x0 0x0 0x0 0x2 &pcie_intc_0 0x1>,
                         <0x0 0x0 0x0 0x3 &pcie_intc_0 0x2>,
                         <0x0 0x0 0x0 0x4 &pcie_intc_0 0x3>;
                        interrupt-map-mask = <0x0 0x0 0x0 0x7>;
                        interrupt-names = "misc";
                        interrupts = <0x0 0x48 0x4>;
                        xlnx,csr-slcr = <0x6 0x0>;
                        xlnx,num-of-bars = <0x2>;
                        xlnx,port-type = <0x1>;
                        interrupt-parent = <&gic>;
                        bus-range = <0x0 0xff>;
                        ranges = <0x2000000 0x0 0xe0010000 0x0 0xe0010000 0x0 0x10000000 0x43000000 0x80 0x0 0x80 0x0 0x0 0x80000000>;
                        msi-map = <0x0 0x4 0x0 0x10000>;
                        reg = <0x6 0x0 0x0 0x1000000 0x0 0xfca10000 0x0 0x1000 0x0 0xfca00000 0x0 0x10000>;
                        reg-names = "cfg", "cpm_slcr", "cpm_crx";
                        phandle = <0xd0>;

                        pcie_intc_0: interrupt-controller {
                                #address-cells = <0x0>;
                                #interrupt-cells = <0x1>;
                                interrupt-controller;
                                phandle = <0x9a>;
                        };
                };

                cpm5_pcie: pcie@fcdd0000 {
                        device_type = "pci";
                        #address-cells = <0x3>;
                        #interrupt-cells = <0x1>;
                        #size-cells = <0x2>;
                        compatible = "xlnx,versal-cpm5-host";
                        status = "disabled";
                        interrupt-map = <0x0 0x0 0x0 0x1 &pcie_intc_2 0x0>,
                         <0x0 0x0 0x0 0x2 &pcie_intc_2 0x1>,
                         <0x0 0x0 0x0 0x3 &pcie_intc_2 0x2>,
                         <0x0 0x0 0x0 0x4 &pcie_intc_2 0x3>;
                        interrupt-map-mask = <0x0 0x0 0x0 0x7>;
                        interrupt-names = "misc";
                        interrupts = <0x0 0x48 0x4>;
                        xlnx,csr-slcr = <0xfce20000>;
                        xlnx,num-of-bars = <0x2>;
                        xlnx,port-type = <0x1>;
                        interrupt-parent = <&gic>;
                        bus-range = <0x0 0xff>;
                        ranges = <0x2000000 0x0 0xe0000000 0x0 0xe0000000 0x0 0x10000000 0x43000000 0x80 0x0 0x80 0x0 0x0 0x80000000>;
                        msi-map = <0x0 0x4 0x0 0x10000>;
                        reg = <0x6 0x0 0x0 0x1000000 0x0 0xfcdd0000 0x0 0x1000 0x0 0xfce20000 0x0 0x10000 0x0 0xfcdc0000 0x0 0x10000>;
                        reg-names = "cfg", "cpm_slcr", "cpm_csr", "cpm_crx";
                        phandle = <0xd1>;

                        pcie_intc_2: interrupt-controller {
                                #address-cells = <0x0>;
                                #interrupt-cells = <0x1>;
                                interrupt-controller;
                                phandle = <0x9b>;
                        };
                };

                watchdog: watchdog@fd4d0000 {
                        compatible = "xlnx,versal-wwdt";
                        status = "disabled";
                        reg = <0x0 0xfd4d0000 0x0 0x10000>;
                        interrupt-names = "wdt", "wwdt_reset_pending", "gwdt", "gwdt_reset_pending";
                        interrupts = <0x0 0x64 0x1 0x0 0x6d 0x1 0x0 0x6c 0x1 0x0 0x6e 0x1>;
                        interrupt-parent = <&gic>;
                        timeout-sec = <0x1e>;
                        clocks = <&versal_clk 0x4c>;
                        power-domains = <&versal_firmware 0x18224029>;
                        phandle = <0xd2>;
                };

                watchdog1: watchdog@ff120000 {
                        compatible = "xlnx,versal-wwdt";
                        status = "disabled";
                        reg = <0x0 0xff120000 0x0 0x10000>;
                        interrupt-parent = <&gic>;
                        interrupt-names = "wdt", "wwdt_reset_pending", "gwdt", "gwdt_reset_pending";
                        interrupts = <0x0 0x31 0x1 0x0 0x45 0x1 0x0 0x46 0x4 0x0 0x47 0x4>;
                        timeout-sec = <0x1e>;
                        clocks = <&versal_clk 0x52>;
                        power-domains = <&versal_firmware 0x18224028>;
                        phandle = <0xd3>;
                };

                xilsem_edac: edac@f2014050 {
                        compatible = "xlnx,versal-xilsem-edac";
                        status = "disabled";
                        reg = <0x0 0xf2014050 0x0 0xc4>;
                        phandle = <0xd4>;
                };

                dma0: pmcdma@f11c0000 {
                        status = "okay";
                        compatible = "xlnx,zynqmp-csudma-1.0";
                        interrupt-parent = <&gic>;
                        interrupts = <0x0 0x83 0x4>;
                        reg = <0x0 0xf11c0000 0x0 0x10000>;
                        xlnx,dma-type = <0x1>;
                        xlnx,ip-name = "psv_pmc_dma";
                        phandle = <0x2e>;
                };

                dma1: pmcdma@f11d0000 {
                        status = "okay";
                        compatible = "xlnx,zynqmp-csudma-1.0";
                        interrupt-parent = <&gic>;
                        interrupts = <0x0 0x84 0x4>;
                        reg = <0x0 0xf11d0000 0x0 0x10000>;
                        xlnx,dma-type = <0x2>;
                        xlnx,ip-name = "psv_pmc_dma";
                        phandle = <0x2f>;
                };

                coresight: coresight@f0800000 {
                        compatible = "xlnx,coresight-1.0";
                        status = "okay";
                        reg = <0x0 0xf0800000 0x0 0x10000>;
                        xlnx,ip-name = "psv_coresight";
                        phandle = <0xa>;
                };

                versal_cips_0_pspmc_0_psv_coresight_fpd_cti1b: versal_cips_0_pspmc_0_psv_coresight_fpd_cti1b@f0bb0000 {
                        compatible = "xlnx,psv-coresight-fpd-cti1b-1.0";
                        status = "okay";
                        xlnx,ip-name = "psv_coresight_fpd_cti1b";
                        reg = <0x0 0xf0bb0000 0x0 0x10000>;
                        phandle = <0x12>;
                };

                versal_cips_0_pspmc_0_psv_coresight_fpd_cti1c: versal_cips_0_pspmc_0_psv_coresight_fpd_cti1c@f0bc0000 {
                        compatible = "xlnx,psv-coresight-fpd-cti1c-1.0";
                        status = "okay";
                        xlnx,ip-name = "psv_coresight_fpd_cti1c";
                        reg = <0x0 0xf0bc0000 0x0 0x10000>;
                        phandle = <0x13>;
                };

                versal_cips_0_pspmc_0_psv_coresight_fpd_cti1d: versal_cips_0_pspmc_0_psv_coresight_fpd_cti1d@f0bd0000 {
                        compatible = "xlnx,psv-coresight-fpd-cti1d-1.0";
                        status = "okay";
                        xlnx,ip-name = "psv_coresight_fpd_cti1d";
                        reg = <0x0 0xf0bd0000 0x0 0x10000>;
                        phandle = <0x14>;
                };

                versal_cips_0_pspmc_0_psv_coresight_lpd_cti: versal_cips_0_pspmc_0_psv_coresight_lpd_cti@f09d0000 {
                        compatible = "xlnx,psv-coresight-lpd-cti-1.0";
                        status = "okay";
                        xlnx,ip-name = "psv_coresight_lpd_cti";
                        reg = <0x0 0xf09d0000 0x0 0x10000>;
                        phandle = <0xd>;
                };

                versal_cips_0_pspmc_0_psv_coresight_pmc_cti: versal_cips_0_pspmc_0_psv_coresight_pmc_cti@f08d0000 {
                        compatible = "xlnx,psv-coresight-pmc-cti-1.0";
                        status = "okay";
                        xlnx,ip-name = "psv_coresight_pmc_cti";
                        reg = <0x0 0xf08d0000 0x0 0x10000>;
                        phandle = <0xb>;
                };

                versal_cips_0_pspmc_0_psv_coresight_r50_cti: versal_cips_0_pspmc_0_psv_coresight_r50_cti@f0a10000 {
                        compatible = "xlnx,psv-coresight-r50-cti-1.0";
                        status = "okay";
                        xlnx,ip-name = "psv_coresight_r50_cti";
                        reg = <0x0 0xf0a10000 0x0 0x10000>;
                        phandle = <0xe>;
                };

                versal_cips_0_pspmc_0_psv_coresight_r51_cti: versal_cips_0_pspmc_0_psv_coresight_r51_cti@f0a50000 {
                        compatible = "xlnx,psv-coresight-r51-cti-1.0";
                        status = "okay";
                        xlnx,ip-name = "psv_coresight_r51_cti";
                        reg = <0x0 0xf0a50000 0x0 0x10000>;
                        phandle = <0xf>;
                };

                versal_cips_0_pspmc_0_psv_cpm: versal_cips_0_pspmc_0_psv_cpm@0 {
                        compatible = "xlnx,psv-cpm-1.0";
                        status = "okay";
                        xlnx,ip-name = "psv_cpm";
                        reg = <0x0 0xfc000000 0x0 0x1000000>;
                        phandle = <0x43>;
                };

                gic: interrupt-controller@f9000000 {
                        phandle = <0x42>;
                        xlnx,ip-name = "psv_acpu_gic";
                        xlnx,apu-gic-its-ctl = <0xf9020000>;
                        status = "okay";
                        interrupts = <0x1 0x9 0x4>;
                        interrupt-parent = <&gic>;
                        interrupt-controller;
                        reg = <0x0 0xf9000000 0x0 0x80000 0x0 0xf9080000 0x0 0x80000>;
                        ranges;
                        #size-cells = <0x2>;
                        #address-cells = <0x2>;
                        #interrupt-cells = <0x3>;
                        compatible = "arm,gic-v3";

                        gic_its: msi-controller@f9020000 {
                                phandle = <0x4>;
                                reg = <0x0 0xf9020000 0x0 0x20000>;
                                #msi-cells = <0x1>;
                                msi-controller;
                                status = "okay";
                                compatible = "arm,gic-v3-its";
                        };
                };
        };

        amba_xppu: indirect-bus@1 {
                compatible = "indirect-bus";
                #address-cells = <0x2>;
                #size-cells = <0x2>;
                phandle = <0x141>;

                lpd_xppu: xppu@ff990000 {
                        compatible = "xlnx,xppu";
                        #firewall-cells = <0x0>;
                        reg = <0x0 0xff990000 0x0 0x2000>;
                        status = "okay";
                        xlnx,ip-name = "psv_lpd_xppu";
                        phandle = <0x63>;
                };

                pmc_xppu: xppu@f1310000 {
                        compatible = "xlnx,xppu";
                        #firewall-cells = <0x0>;
                        reg = <0x0 0xf1310000 0x0 0x2000>;
                        status = "okay";
                        xlnx,ip-name = "psv_pmc_xppu";
                        phandle = <0x3f>;
                };

                pmc_xppu_npi: xppu@f1300000 {
                        compatible = "xlnx,xppu";
                        #firewall-cells = <0x0>;
                        reg = <0x0 0xf1300000 0x0 0x2000>;
                        status = "okay";
                        xlnx,ip-name = "psv_pmc_xppu_npi";
                        phandle = <0x3e>;
                };
        };

        amba_xmpu: indirect-bus@2 {
                compatible = "indirect-bus";
                #address-cells = <0x2>;
                #size-cells = <0x2>;
                phandle = <0x142>;

                fpd_xmpu: xmpu@fd390000 {
                        compatible = "xlnx,xmpu";
                        #firewall-cells = <0x0>;
                        reg = <0x0 0xfd390000 0x0 0x1000>;
                        status = "okay";
                        xlnx,ip-name = "psv_fpd_slave_xmpu";
                        phandle = <0x48>;
                };

                pmc_xmpu: xmpu@f12f0000 {
                        compatible = "xlnx,xmpu";
                        #firewall-cells = <0x0>;
                        reg = <0x0 0xf12f0000 0x0 0x1000>;
                        status = "okay";
                        xlnx,ip-name = "psv_pmc_xmpu";
                        phandle = <0x3d>;
                };

                ocm_xmpu: xmpu@ff980000 {
                        compatible = "xlnx,xmpu";
                        #firewall-cells = <0x0>;
                        reg = <0x0 0xff980000 0x0 0x1000>;
                        status = "okay";
                        xlnx,ip-name = "psv_ocm_xmpu";
                        phandle = <0x62>;
                };

                ddrmc_xmpu_0: xmpu@f6080000 {
                        compatible = "xlnx,xmpu";
                        #firewall-cells = <0x0>;
                        reg = <0x0 0xf6080000 0x0 0x1000>;
                        status = "disabled";
                        phandle = <0x143>;
                };

                ddrmc_xmpu_1: xmpu@f6220000 {
                        compatible = "xlnx,xmpu";
                        #firewall-cells = <0x0>;
                        reg = <0x0 0xf6220000 0x0 0x1000>;
                        status = "disabled";
                        phandle = <0x144>;
                };

                ddrmc_xmpu_2: xmpu@f6390000 {
                        compatible = "xlnx,xmpu";
                        #firewall-cells = <0x0>;
                        reg = <0x0 0xf6390000 0x0 0x1000>;
                        status = "disabled";
                        phandle = <0x145>;
                };

                ddrmc_xmpu_3: xmpu@f6500000 {
                        compatible = "xlnx,xmpu";
                        #firewall-cells = <0x0>;
                        reg = <0x0 0xf6500000 0x0 0x1000>;
                        status = "disabled";
                        phandle = <0x146>;
                };
        };

        pl_alt_ref: pl-alt-ref {
                bootph-all;
                compatible = "fixed-clock";
                #clock-cells = <0x0>;
                clock-frequency = <0x1fca055>;
                clock-output-names = "pl_alt_ref_clk";
                phandle = <0x9d>;
        };

        ref: ref {
                bootph-all;
                compatible = "fixed-clock";
                #clock-cells = <0x0>;
                clock-frequency = <0x1fca034>;
                clock-output-names = "ref_clk";
                phandle = <0x9c>;
        };

        can0_clk: can0-clk {
                #clock-cells = <0x0>;
                compatible = "fixed-factor-clock";
                clocks = <&versal_clk 0x60>;
                clock-div = <0x2>;
                clock-mult = <0x1>;
                clock-output-names = "can0_clk";
                phandle = <0x95>;
        };

        can1_clk: can1-clk {
                #clock-cells = <0x0>;
                compatible = "fixed-factor-clock";
                clocks = <&versal_clk 0x61>;
                clock-div = <0x2>;
                clock-mult = <0x1>;
                clock-output-names = "can1_clk";
                phandle = <0x96>;
        };

        firmware {

                versal_firmware: versal-firmware {
                        compatible = "xlnx,versal-firmware";
                        interrupt-parent = <&gic>;
                        bootph-all;
                        method = "smc";
                        #power-domain-cells = <0x1>;
                        phandle = <0x74>;

                        versal_clk: clock-controller {
                                bootph-all;
                                #clock-cells = <0x1>;
                                compatible = "xlnx,versal-clk";
                                clocks = <&ref>,
                                 <&pl_alt_ref>;
                                clock-names = "ref", "pl_alt_ref";
                                phandle = <0x75>;
                        };

                        zynqmp_power: power-management {
                                compatible = "xlnx,zynqmp-power";
                                phandle = <0x147>;
                        };

                        versal_reset: reset-controller {
                                compatible = "xlnx,versal-reset";
                                #reset-cells = <0x1>;
                                phandle = <0x99>;
                        };

                        pinctrl0: pinctrl {
                                compatible = "xlnx,versal-pinctrl";
                                phandle = <0x148>;
                        };

                        versal_sec_cfg: versal-sec-cfg {
                                compatible = "xlnx,versal-sec-cfg";
                                #address-cells = <0x1>;
                                #size-cells = <0x1>;
                                phandle = <0x149>;

                                nvmem-layout {
                                        compatible = "fixed-layout";
                                        #address-cells = <0x1>;
                                        #size-cells = <0x1>;

                                        bbram_zeroize: bbram-zeroize@4 {
                                                reg = <0x4 0x4>;
                                                phandle = <0x14a>;
                                        };

                                        bbram_key: bbram-key@10 {
                                                reg = <0x10 0x20>;
                                                phandle = <0x14b>;
                                        };

                                        bbram_usr: bbram-usr@30 {
                                                reg = <0x30 0x4>;
                                                phandle = <0x14c>;
                                        };

                                        bbram_lock: bbram-lock@48 {
                                                reg = <0x48 0x4>;
                                                phandle = <0x14d>;
                                        };

                                        user_key0: user-key@110 {
                                                reg = <0x110 0x20>;
                                                phandle = <0x14e>;
                                        };

                                        user_key1: user-key@130 {
                                                reg = <0x130 0x20>;
                                                phandle = <0x14f>;
                                        };

                                        user_key2: user-key@150 {
                                                reg = <0x150 0x20>;
                                                phandle = <0x150>;
                                        };

                                        user_key3: user-key@170 {
                                                reg = <0x170 0x20>;
                                                phandle = <0x151>;
                                        };

                                        user_key4: user-key@190 {
                                                reg = <0x190 0x20>;
                                                phandle = <0x152>;
                                        };

                                        user_key5: user-key@1b0 {
                                                reg = <0x1b0 0x20>;
                                                phandle = <0x153>;
                                        };

                                        user_key6: user-key@1d0 {
                                                reg = <0x1d0 0x20>;
                                                phandle = <0x154>;
                                        };

                                        user_key7: user-key@1f0 {
                                                reg = <0x1f0 0x20>;
                                                phandle = <0x155>;
                                        };
                                };
                        };
                };
        };

        axi_noc_0_ddr_memory: memory@00000000 {
                compatible = "xlnx,axi-noc-1.1";
                xlnx,ip-name = "axi_noc";
                device_type = "memory";
                reg = <0x0 0x0 0x0 0x80000000 0x8 0x0 0x0 0x80000000>;
                memory_type = "memory";
                phandle = <0x3>;
        };

        chosen {
                stdout-path = "serial0:115200n8";
        };

        aliases {
                serial0 = "/axi/serial@ff000000";
                serial1 = "/axi/serial@ff010000";
                serial2 = "/axi/coresight@f0800000";
                i2c0 = "/axi/i2c@ff020000";
                i2c1 = "/axi/i2c@ff030000";
                mmc0 = "/axi/mmc@f1040000";
                spi0 = "/axi/spi@f1010000";
                rtc0 = "/axi/rtc@f12a0000";
        };

        __symbols__ {
                cpus_a72 = "/cpus-a72@0";
                psv_cortexa72_0 = "/cpus-a72@0/cpu@0";
                psv_cortexa72_1 = "/cpus-a72@0/cpu@1";
                CPU_SLEEP_0 = "/cpus-a72@0/idle-states/cpu-sleep-0";
                cpu_opp_table = "/opp-table-cpu";
                dcc = "/dcc";
                fpga = "/fpga-region";
                psci = "/psci";
                timer = "/timer";
                versal_fpga = "/versal-fpga";
                sensor0 = "/versal-thermal-sensor";
                versal_thermal = "/thermal-zones/versal-thermal";
                temp_alert = "/thermal-zones/versal-thermal/trips/temp-alert";
                ot_crit = "/thermal-zones/versal-thermal/trips/ot-crit";
                amba_apu = "/apu-bus";
                gic_its = "/axi/interrupt-controller@f9000000/msi-controller@f9020000";
                amba = "/axi";
                imux = "/axi/interrupt-multiplex";
                can0 = "/axi/can@ff060000";
                can1 = "/axi/can@ff070000";
                cci = "/axi/cci@fd000000";
                cci_pmu = "/axi/cci@fd000000/pmu@10000";
                lpd_dma_chan0 = "/axi/dma-controller@ffa80000";
                lpd_dma_chan1 = "/axi/dma-controller@ffa90000";
                lpd_dma_chan2 = "/axi/dma-controller@ffaa0000";
                lpd_dma_chan3 = "/axi/dma-controller@ffab0000";
                lpd_dma_chan4 = "/axi/dma-controller@ffac0000";
                lpd_dma_chan5 = "/axi/dma-controller@ffad0000";
                lpd_dma_chan6 = "/axi/dma-controller@ffae0000";
                lpd_dma_chan7 = "/axi/dma-controller@ffaf0000";
                gem0 = "/axi/ethernet@ff0c0000";
                gem1 = "/axi/ethernet@ff0d0000";
                gpio0 = "/axi/gpio@ff0b0000";
                gpio1 = "/axi/gpio@f1020000";
                i2c0 = "/axi/i2c@ff020000";
                regulator_u50 = "/axi/i2c@ff020000/regulator@60";
                regulator_uXX = "/axi/i2c@ff020000/regulator@61";
                sensor_u30 = "/axi/i2c@ff020000/temp-sensor@1a";
                gpio_u43 = "/axi/i2c@ff020000/gpio@20";
                ina_u48 = "/axi/i2c@ff020000/power-sensor@40";
                ina_u49 = "/axi/i2c@ff020000/power-sensor@41";
                i2c1 = "/axi/i2c@ff030000";
                qsfp_power = "/axi/i2c@ff030000/gpio@21";
                i2c_qsfp1 = "/axi/i2c@ff030000/i2c-mux@70";
                qsfp1 = "/axi/i2c@ff030000/i2c-mux@70/i2c@0/gpio@20";
                qsfp2 = "/axi/i2c@ff030000/i2c-mux@70/i2c@2/gpio@20";
                i2c_qsfp3 = "/axi/i2c@ff030000/i2c-mux@71";
                qsfp3 = "/axi/i2c@ff030000/i2c-mux@71/i2c@0/gpio@20";
                qsfp4 = "/axi/i2c@ff030000/i2c-mux@71/i2c@2/gpio@20";
                pcie = "/axi/i2c@ff030000/i2c-mux@72";
                i2c2 = "/axi/i2c@f1000000";
                mc0 = "/axi/memory-controller@f6150000";
                mc1 = "/axi/memory-controller@f62c0000";
                mc2 = "/axi/memory-controller@f6430000";
                mc3 = "/axi/memory-controller@f65a0000";
                ocm = "/axi/memory-controller@ff960000";
                rtc = "/axi/rtc@f12a0000";
                sdhci0 = "/axi/mmc@f1040000";
                sdhci1 = "/axi/mmc@f1050000";
                serial0 = "/axi/serial@ff000000";
                serial1 = "/axi/serial@ff010000";
                smmu = "/axi/iommu@fd800000";
                ospi = "/axi/spi@f1010000";
                ospi_flash = "/axi/spi@f1010000/flash@0";
                qspi = "/axi/spi@f1030000";
                spi0 = "/axi/spi@ff040000";
                spi1 = "/axi/spi@ff050000";
                sysmon0 = "/axi/sysmon@f1270000";
                sysmon1 = "/axi/sysmon@109270000";
                sysmon2 = "/axi/sysmon@111270000";
                sysmon3 = "/axi/sysmon@119270000";
                ttc0 = "/axi/timer@ff0e0000";
                ttc1 = "/axi/timer@ff0f0000";
                ttc2 = "/axi/timer@ff100000";
                ttc3 = "/axi/timer@ff110000";
                usb0 = "/axi/usb@ff9d0000";
                dwc3_0 = "/axi/usb@ff9d0000/usb@fe200000";
                cpm_pciea = "/axi/pci@fca10000";
                pcie_intc_0 = "/axi/pci@fca10000/interrupt-controller";
                cpm5_pcie = "/axi/pcie@fcdd0000";
                pcie_intc_2 = "/axi/pcie@fcdd0000/interrupt-controller";
                watchdog = "/axi/watchdog@fd4d0000";
                watchdog1 = "/axi/watchdog@ff120000";
                xilsem_edac = "/axi/edac@f2014050";
                dma0 = "/axi/pmcdma@f11c0000";
                dma1 = "/axi/pmcdma@f11d0000";
                coresight = "/axi/coresight@f0800000";
                versal_cips_0_pspmc_0_psv_coresight_fpd_cti1b = "/axi/versal_cips_0_pspmc_0_psv_coresight_fpd_cti1b@f0bb0000";
                versal_cips_0_pspmc_0_psv_coresight_fpd_cti1c = "/axi/versal_cips_0_pspmc_0_psv_coresight_fpd_cti1c@f0bc0000";
                versal_cips_0_pspmc_0_psv_coresight_fpd_cti1d = "/axi/versal_cips_0_pspmc_0_psv_coresight_fpd_cti1d@f0bd0000";
                versal_cips_0_pspmc_0_psv_coresight_lpd_cti = "/axi/versal_cips_0_pspmc_0_psv_coresight_lpd_cti@f09d0000";
                versal_cips_0_pspmc_0_psv_coresight_pmc_cti = "/axi/versal_cips_0_pspmc_0_psv_coresight_pmc_cti@f08d0000";
                versal_cips_0_pspmc_0_psv_coresight_r50_cti = "/axi/versal_cips_0_pspmc_0_psv_coresight_r50_cti@f0a10000";
                versal_cips_0_pspmc_0_psv_coresight_r51_cti = "/axi/versal_cips_0_pspmc_0_psv_coresight_r51_cti@f0a50000";
                versal_cips_0_pspmc_0_psv_cpm = "/axi/versal_cips_0_pspmc_0_psv_cpm@0";
                amba_xppu = "/indirect-bus@1";
                lpd_xppu = "/indirect-bus@1/xppu@ff990000";
                pmc_xppu = "/indirect-bus@1/xppu@f1310000";
                pmc_xppu_npi = "/indirect-bus@1/xppu@f1300000";
                amba_xmpu = "/indirect-bus@2";
                fpd_xmpu = "/indirect-bus@2/xmpu@fd390000";
                pmc_xmpu = "/indirect-bus@2/xmpu@f12f0000";
                ocm_xmpu = "/indirect-bus@2/xmpu@ff980000";
                ddrmc_xmpu_0 = "/indirect-bus@2/xmpu@f6080000";
                ddrmc_xmpu_1 = "/indirect-bus@2/xmpu@f6220000";
                ddrmc_xmpu_2 = "/indirect-bus@2/xmpu@f6390000";
                ddrmc_xmpu_3 = "/indirect-bus@2/xmpu@f6500000";
                pl_alt_ref = "/pl-alt-ref";
                ref = "/ref";
                can0_clk = "/can0-clk";
                can1_clk = "/can1-clk";
                versal_firmware = "/firmware/versal-firmware";
                versal_clk = "/firmware/versal-firmware/clock-controller";
                zynqmp_power = "/firmware/versal-firmware/power-management";
                versal_reset = "/firmware/versal-firmware/reset-controller";
                pinctrl0 = "/firmware/versal-firmware/pinctrl";
                versal_sec_cfg = "/firmware/versal-firmware/versal-sec-cfg";
                bbram_zeroize = "/firmware/versal-firmware/versal-sec-cfg/nvmem-layout/bbram-zeroize@4";
                bbram_key = "/firmware/versal-firmware/versal-sec-cfg/nvmem-layout/bbram-key@10";
                bbram_usr = "/firmware/versal-firmware/versal-sec-cfg/nvmem-layout/bbram-usr@30";
                bbram_lock = "/firmware/versal-firmware/versal-sec-cfg/nvmem-layout/bbram-lock@48";
                user_key0 = "/firmware/versal-firmware/versal-sec-cfg/nvmem-layout/user-key@110";
                user_key1 = "/firmware/versal-firmware/versal-sec-cfg/nvmem-layout/user-key@130";
                user_key2 = "/firmware/versal-firmware/versal-sec-cfg/nvmem-layout/user-key@150";
                user_key3 = "/firmware/versal-firmware/versal-sec-cfg/nvmem-layout/user-key@170";
                user_key4 = "/firmware/versal-firmware/versal-sec-cfg/nvmem-layout/user-key@190";
                user_key5 = "/firmware/versal-firmware/versal-sec-cfg/nvmem-layout/user-key@1b0";
                user_key6 = "/firmware/versal-firmware/versal-sec-cfg/nvmem-layout/user-key@1d0";
                user_key7 = "/firmware/versal-firmware/versal-sec-cfg/nvmem-layout/user-key@1f0";
                axi_noc_0_ddr_memory = "/memory@00000000";
                gic = "/axi/interrupt-controller@f9000000";
        };
};
